VERSION "1"

NS_ :

BS_:

BU_: BMS ECU

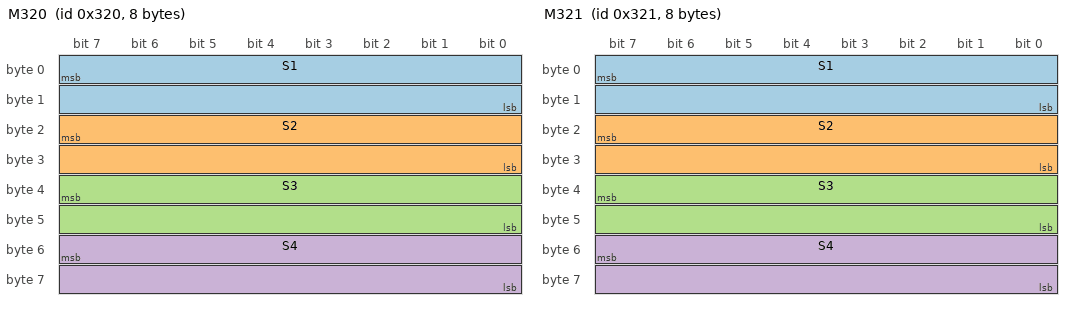
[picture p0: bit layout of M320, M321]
BO_ 800 M320: 8 BMS
 SG_ S1 : 7|16@0+ (1,0) [0|65.535] ""  ECU
 SG_ S2 : 23|16@0+ (1,0) [0|65.535] ""  ECU
 SG_ S3 : 39|16@0+ (1,0) [0|65.535] ""  ECU
 SG_ S4 : 55|16@0+ (1,0) [0|65.535] "?"  ECU

BO_ 801 M321: 8 BMS
 SG_ S1 : 7|16@0+ (1,0) [0|65.535] ""  ECU
 SG_ S2 : 23|16@0+ (1,0) [0|65.535] "V_max/100"  ECU
 SG_ S3 : 39|16@0+ (1,0) [0|65.535] ""  ECU
 SG_ S4 : 55|16@0+ (1,0) [0|65.535] "V_min/100"  ECU

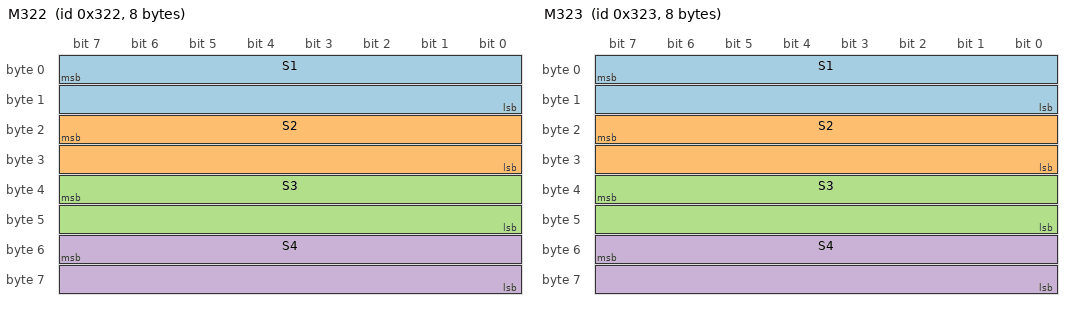
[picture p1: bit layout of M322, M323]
BO_ 802 M322: 8 BMS
 SG_ S1 : 7|16@0+ (1,0) [0|65.535] ""  ECU
 SG_ S2 : 23|16@0+ (1,0) [0|65.535] "A_in/100"  ECU
 SG_ S3 : 39|16@0+ (1,0) [0|65.535] ""  ECU
 SG_ S4 : 55|16@0+ (1,0) [0|65.535] "A_out/100"  ECU

BO_ 803 M323: 8 BMS
 SG_ S1 : 7|16@0+ (1,0) [0|65.535] ""  ECU
 SG_ S2 : 23|16@0+ (1,0) [0|65.535] "V_avg/100"  ECU
 SG_ S3 : 39|16@0- (1,0) [0|65.535] ""  ECU
 SG_ S4 : 55|16@0- (1,0) [0|65.535] ""  ECU

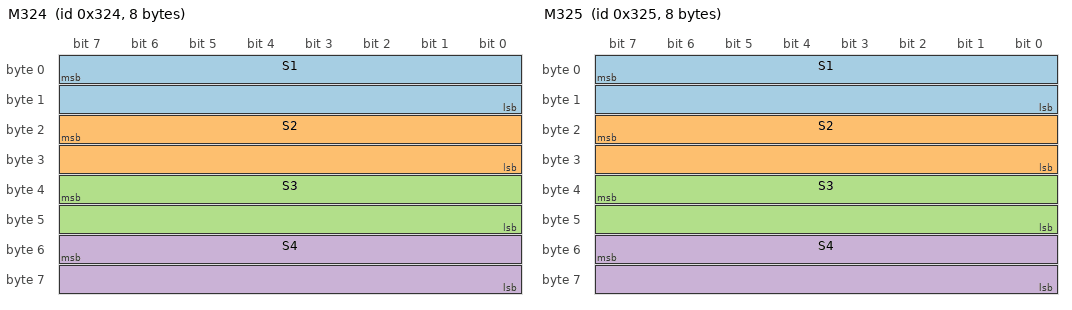
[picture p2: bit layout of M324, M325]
BO_ 804 M324: 8 BMS
 SG_ S1 : 7|16@0+ (1,0) [0|65.535] "C_avg/10"  ECU
 SG_ S2 : 23|16@0+ (1,0) [0|65.535] "SOC"  ECU
 SG_ S3 : 39|16@0+ (1,0) [0|65.535] ""  ECU
 SG_ S4 : 55|16@0+ (1,0) [0|65.535] ""  ECU

BO_ 805 M325: 8 BMS
 SG_ S1 : 7|16@0+ (1,0) [0|65.535] ""  ECU
 SG_ S2 : 23|16@0+ (1,0) [0|65.535] ""  ECU
 SG_ S3 : 39|16@0+ (1,0) [0|65.535] ""  ECU
 SG_ S4 : 55|16@0+ (1,0) [0|65.535] ""  ECU

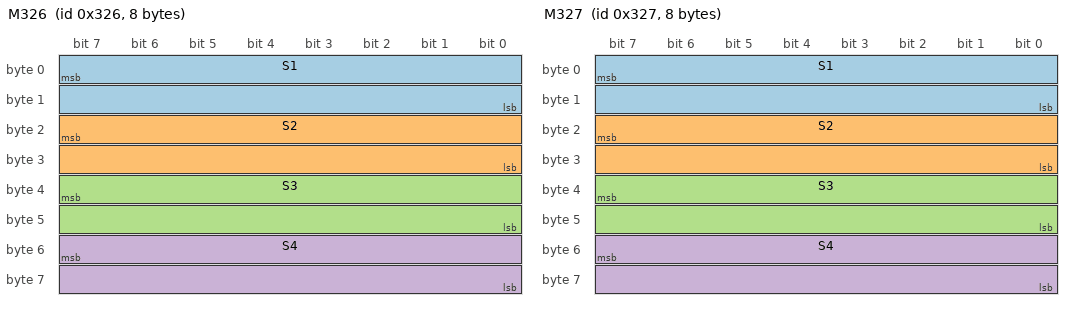
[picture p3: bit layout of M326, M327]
BO_ 806 M326: 8 BMS
 SG_ S1 : 7|16@0+ (1,0) [0|65.535] "-"  ECU
 SG_ S2 : 23|16@0+ (1,0) [0|65.535] "-"  ECU
 SG_ S3 : 39|16@0+ (1,0) [0|65.535] "SOH"  ECU
 SG_ S4 : 55|16@0+ (1,0) [0|65.535] "Ah?"  ECU

BO_ 807 M327: 8 BMS
 SG_ S1 : 7|16@0+ (1,0) [0|65.535] ""  ECU
 SG_ S2 : 23|16@0+ (1,0) [0|65.535] ""  ECU
 SG_ S3 : 39|16@0+ (1,0) [0|65.535] ""  ECU
 SG_ S4 : 55|16@0+ (1,0) [0|65.535] ""  ECU

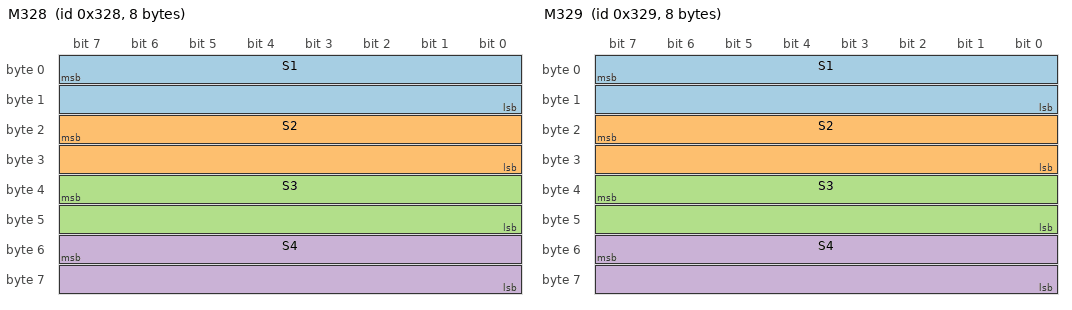
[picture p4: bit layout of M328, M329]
BO_ 808 M328: 8 BMS
 SG_ S1 : 7|16@0+ (1,0) [0|65.535] ""  ECU
 SG_ S2 : 23|16@0+ (1,0) [0|65.535] ""  ECU
 SG_ S3 : 39|16@0+ (1,0) [0|65.535] ""  ECU
 SG_ S4 : 55|16@0+ (1,0) [0|65.535] ""  ECU

BO_ 809 M329: 8 BMS
 SG_ S1 : 7|16@0+ (1,0) [0|65.535] ""  ECU
 SG_ S2 : 23|16@0+ (1,0) [0|65.535] ""  ECU
 SG_ S3 : 39|16@0+ (1,0) [0|65.535] ""  ECU
 SG_ S4 : 55|16@0+ (1,0) [0|65.535] ""  ECU

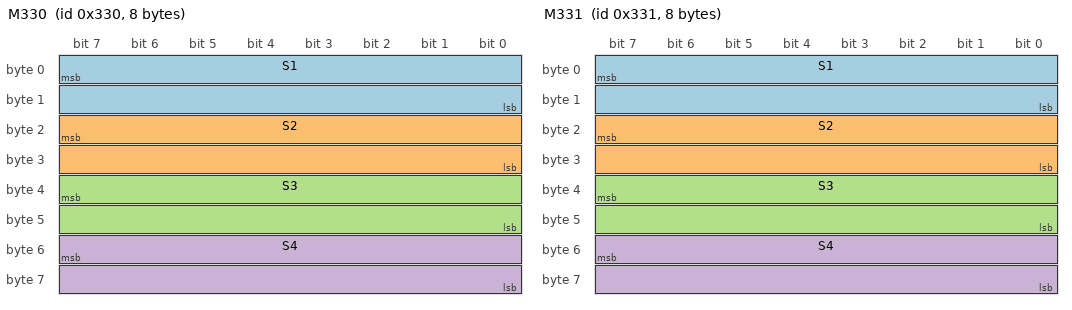
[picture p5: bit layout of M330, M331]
BO_ 816 M330: 8 BMS
 SG_ S1 : 7|16@0+ (1,0) [0|65.535] ""  ECU
 SG_ S2 : 23|16@0+ (1,0) [0|65.535] ""  ECU
 SG_ S3 : 39|16@0+ (1,0) [0|65.535] ""  ECU
 SG_ S4 : 55|16@0+ (1,0) [0|65.535] ""  ECU

BO_ 817 M331: 8 BMS
 SG_ S1 : 7|16@0+ (1,0) [0|65.535] ""  ECU
 SG_ S2 : 23|16@0+ (1,0) [0|65.535] ""  ECU
 SG_ S3 : 39|16@0+ (1,0) [0|65.535] ""  ECU
 SG_ S4 : 55|16@0+ (1,0) [0|65.535] ""  ECU

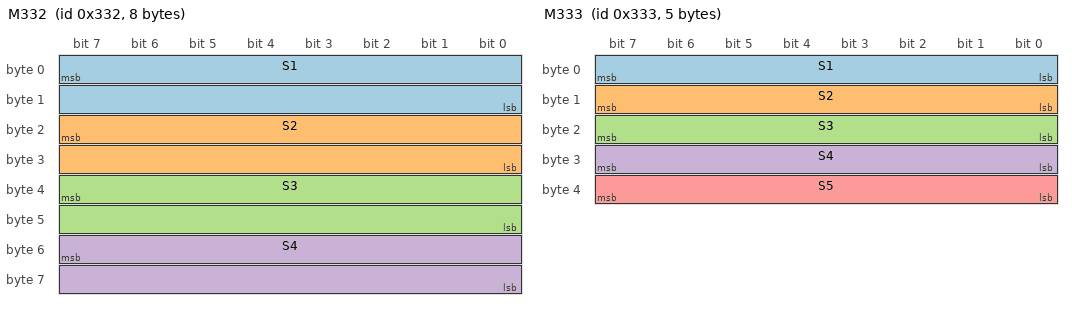
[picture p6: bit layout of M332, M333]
BO_ 818 M332: 8 BMS
 SG_ S1 : 7|16@0+ (1,0) [0|65.535] ""  ECU
 SG_ S2 : 23|16@0+ (1,0) [0|65.535] ""  ECU
 SG_ S3 : 39|16@0+ (1,0) [0|65.535] ""  ECU
 SG_ S4 : 55|16@0+ (1,0) [0|65.535] ""  ECU

BO_ 819 M333: 5 BMS
 SG_ S1 : 7|8@0+ (1,0) [0|65.535] ""  ECU
 SG_ S2 : 15|8@0+ (1,0) [0|65.535] ""  ECU
 SG_ S3 : 23|8@0+ (1,0) [0|65.535] ""  ECU
 SG_ S4 : 31|8@0+ (1,0) [0|65.535] ""  ECU
 SG_ S5 : 39|8@0+ (1,0) [0|65.535] ""  ECU

BO_ 2508259072 Unknown: 2 BMS
 SG_ S1 : 7|16@0+ (1,0) [0|65.535] ""  ECU
